# RFM register map
File version: 1.0
Radio
Registers are 32-bit, read-write, reset 0x0 unless marked. A register's access mark holds for its fields unless they carry their own. Offsets are from the block's base; lines under a group give offsets from that group; [hi:lo] are bit positions; {n}, {i} and the like mark numbered series; 'fields as' and 'values as' point back to an identical list; <NAME> marks a mode.

## Memory map
0x00000000 TIMER0 size 0x100 — 32 Timer / Counter, counting up or down from different sources

## TIMER0 — 32 Timer / Counter, counting up or down from different sources
Base 0x00000000
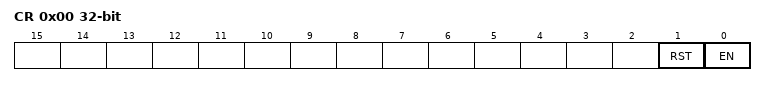
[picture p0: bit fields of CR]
0x00 CR — Control Register
  [1] RST wo — Reset Timer
    0=Reserved (Write as ZERO if necessary); 1=Reset_Timer (Reset the Timer)
  [0] EN — Enable
    0=Disable (Timer is disabled and does not operate); 1=Enable (Timer is enabled and can operate)
